# apollo2 register map
Vendor: Ambiq Micro; Series: Apollo; File version: 1.0
CPU: CM4 r1p0, little endian, MPU, FPU, 3 interrupt priority bits
Registers are 32-bit, read-write, reset 0x0 unless marked. A register's access mark holds for its fields unless they carry their own. Offsets are from the block's base; [hi:lo] are bit positions; 'fields as' and 'values as' point back to an identical list.

## CLKGEN — Clock Generator
Base 0x40004000
0x00 CALXT — XT Oscillator Control
  [10:0] CALXT — XT Oscillator calibration value
0x04 CALRC — RC Oscillator Control
  [17:0] CALRC — LFRC Oscillator calibration value
0x08 ACALCTR — Autocalibration Counter
  [23:0] ACALCTR — Autocalibration Counter result.
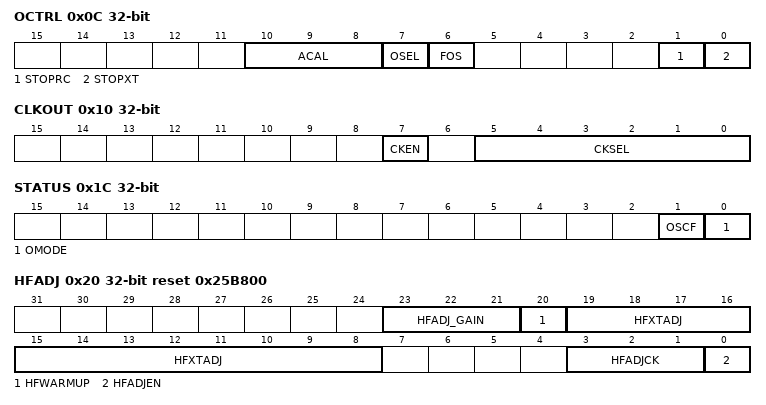
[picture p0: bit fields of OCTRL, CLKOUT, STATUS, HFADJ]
0x0C OCTRL — Oscillator Control
  [10:8] ACAL — Autocalibration control
    0=DIS (Disable Autocalibration value.); 2=1024SEC (Autocalibrate every 1024 seconds value.); 3=512SEC (Autocalibrate every 512 seconds value.); 6=XTFREQ (Frequency measurement using XT value.); 7=EXTFREQ (Frequency measurement using external clock value.)
  [7] OSEL — Selects the RTC oscillator (1 => LFRC, 0 => XT)
    0=RTC_XT (RTC uses the XT value.); 1=RTC_LFRC (RTC uses the LFRC value.)
  [6] FOS — Oscillator switch on failure function
    0=DIS (Disable the oscillator switch on failure function value.); 1=EN (Enable the oscillator switch on failure function value.)
  [1] STOPRC — Stop the LFRC Oscillator to the RTC
    0=EN (Enable the LFRC Oscillator to drive the RTC value.); 1=STOP (Stop the LFRC Oscillator when driving the RTC value.)
  [0] STOPXT — Stop the XT Oscillator to the RTC
    0=EN (Enable the XT Oscillator to drive the RTC value.); 1=STOP (Stop the XT Oscillator when driving the RTC value.)
0x10 CLKOUT — CLKOUT Frequency Select
  [7] CKEN — Enable the CLKOUT signal
    0=DIS (Disable CLKOUT value.); 1=EN (Enable CLKOUT value.)
  [5:0] CKSEL — CLKOUT signal select
    0=LFRC (LFRC value.); 1=XT_DIV2 (XT / 2 value.); 2=XT_DIV4 (XT / 4 value.); 3=XT_DIV8 (XT / 8 value.); 4=XT_DIV16 (XT / 16 value.); 5=XT_DIV32 (XT / 32 value.); 16=RTC_1Hz (1 Hz as selected in RTC value.); 22=XT_DIV2M (XT / 2^21 value.); 23=XT (XT value.); 24=CG_100Hz (100 Hz as selected in CLKGEN value.); 25=HFRC (HFRC value.); 26=HFRC_DIV4 (HFRC / 4 value.); 27=HFRC_DIV8 (HFRC / 8 value.); 28=HFRC_DIV16 (HFRC / 16 value.); 29=HFRC_DIV64 (HFRC / 64 value.); 30=HFRC_DIV128 (HFRC / 128 value.); 31=HFRC_DIV256 (HFRC / 256 value.); 32=HFRC_DIV512 (HFRC / 512 value.); 34=FLASH_CLK (Flash Clock value.); 35=LFRC_DIV2 (LFRC / 2 value.); 36=LFRC_DIV32 (LFRC / 32 value.); 37=LFRC_DIV512 (LFRC / 512 value.); 38=LFRC_DIV32K (LFRC / 32768 value.); 39=XT_DIV256 (XT / 256 value.); 40=XT_DIV8K (XT / 8192 value.); 41=XT_DIV64K (XT / 2^16 value.); 42=ULFRC_DIV16 (Uncal LFRC / 16 value.); 43=ULFRC_DIV128 (Uncal LFRC / 128 value.); 44=ULFRC_1Hz (Uncal LFRC / 1024 value.); 45=ULFRC_DIV4K (Uncal LFRC / 4096 value.); 46=ULFRC_DIV1M (Uncal LFRC / 2^20 value.); 47=HFRC_DIV64K (HFRC / 2^16 value.); 48=HFRC_DIV16M (HFRC / 2^24 value.); 49=LFRC_DIV2M (LFRC / 2^20 value.); 50=HFRCNE (HFRC (not autoenabled) value.); 51=HFRCNE_DIV8 (HFRC / 8 (not autoenabled) value.); 53=XTNE (XT (not autoenabled) value.); 54=XTNE_DIV16 (XT / 16 (not autoenabled) value.); 55=LFRCNE_DIV32 (LFRC / 32 (not autoenabled) value.); 57=LFRCNE (LFRC (not autoenabled) - Default for undefined values value.)
0x14 CLKKEY — Key Register for Clock Control Register
  [31:0] CLKKEY — Key register value.
    71=Key (Key value.)
0x18 CCTRL reset 0x1 — HFRC Clock Control
  [0] CORESEL — Core Clock divisor
    0=HFRC (Core Clock is HFRC value.); 1=HFRC_DIV2 (Core Clock is HFRC / 2 value.)
0x1C STATUS — Clock Generator Status
  [1] OSCF — XT Oscillator is enabled but not oscillating
  [0] OMODE — Current RTC oscillator (1 => LFRC, 0 => XT)
0x20 HFADJ reset 0x25B800 — HFRC Adjustment
  [23:21] HFADJ_GAIN — Gain control for HFRC adjustment
    0=Gain_of_1 (HF Adjust with Gain of 1 value.); 1=Gain_of_1_in_2 (HF Adjust with Gain of 0.5 value.); 2=Gain_of_1_in_4 (HF Adjust with Gain of 0.25 value.); 3=Gain_of_1_in_8 (HF Adjust with Gain of 0.125 value.); 4=Gain_of_1_in_16 (HF Adjust with Gain of 0.0625 value.); 5=Gain_of_1_in_32 (HF Adjust with Gain of 0.03125 value.)
  [20] HFWARMUP — XT warmup period for HFRC adjustment
    0=1SEC (Autoadjust XT warmup period = 1-2 seconds value.); 1=2SEC (Autoadjust XT warmup period = 2-4 seconds value.)
  [19:8] HFXTADJ — Target HFRC adjustment value.
  [3:1] HFADJCK — Repeat period for HFRC adjustment
    0=4SEC (Autoadjust repeat period = 4 seconds value.); 1=16SEC (Autoadjust repeat period = 16 seconds value.); 2=32SEC (Autoadjust repeat period = 32 seconds value.); 3=64SEC (Autoadjust repeat period = 64 seconds value.); 4=128SEC (Autoadjust repeat period = 128 seconds value.); 5=256SEC (Autoadjust repeat period = 256 seconds value.); 6=512SEC (Autoadjust repeat period = 512 seconds value.); 7=1024SEC (Autoadjust repeat period = 1024 seconds value.)
  [0] HFADJEN — HFRC adjustment control
    0=DIS (Disable the HFRC adjustment value.); 1=EN (Enable the HFRC adjustment value.)
0x24 HFVAL — HFADJ readback
  [10:0] HFTUNERB — Current HFTUNE value
0x28 CLOCKEN — Clock Enable Status
  [31:0] CLOCKEN — Clock enable status
    1=ADC_CLKEN (Clock enable for the ADC. value.); 2=CTIMER_CLKEN (Clock enable for the CTIMER. value.); 4=CTIMER0A_CLKEN (Clock enable for the CTIMER0A. value.); 8=CTIMER0B_CLKEN (Clock enable for the CTIMER0B. value.); 16=CTIMER1A_CLKEN (Clock enable for the CTIMER1A. value.); 32=CTIMER1B_CLKEN (Clock enable for the CTIMER1B. value.); 64=CTIMER2A_CLKEN (Clock enable for the CTIMER2A. value.); 128=CTIMER2B_CLKEN (Clock enable for the CTIMER2B. value.); 0x100=CTIMER3A_CLKEN (Clock enable for the CTIMER3A. value.); 0x200=CTIMER3B_CLKEN (Clock enable for the CTIMER3B. value.); 0x400=IOMSTR0_CLKEN (Clock enable for the IO Master 0. value.); 0x800=IOMSTR1_CLKEN (Clock enable for the IO Master 1. value.); 0x1000=IOMSTR2_CLKEN (Clock enable for the IO Master 2. value.); 0x2000=IOMSTR3_CLKEN (Clock enable for the IO Master 3. value.); 0x4000=IOMSTR4_CLKEN (Clock enable for the IO Master 4. value.); 0x8000=IOMSTR5_CLKEN (Clock enable for the IO Master 5. value.); 0x10000=IOMSTRIFC0_CLKEN (Clock enable for the IO Master IFC0. value.); 0x20000=IOMSTRIFC1_CLKEN (Clock enable for the IO Master IFC1. value.); 0x40000=IOMSTRIFC2_CLKEN (Clock enable for the IO Master IFC2. value.); 0x80000=IOMSTRIFC3_CLKEN (Clock enable for the IO Master IFC3. value.); 0x100000=IOMSTRIFC4_CLKEN (Clock enable for the IO Master IFC4. value.); 0x200000=IOMSTRIFC5_CLKEN (Clock enable for the IO Master IFC5. value.); 0x400000=IOSLAVE_CLKEN (Clock enable for the IO Slave. value.); 0x800000=PDM_CLKEN (Clock enable for the PDM. value.); 0x1000000=PDMIFC_CLKEN (Clock enable for the PDM IFC. value.); 0x2000000=RSTGEN_CLKEN (Clock enable for the RSTGEN. value.); 0x4000000=SRAM_WIPE_CLKEN (Clock enable for the SRAM_WIPE. value.); 0x8000000=STIMER_CLKEN (Clock enable for the STIMER. value.); 0x10000000=STIMER_CNT_CLKEN (Clock enable for the STIMER_CNT. value.); 0x20000000=TPIU_CLKEN (Clock enable for the TPIU. value.); 0x40000000=UART0_HCLK_CLKEN (Clock enable for the UART0_HCLK. value.); 0x80000000=UART0HF_CLKEN (Clock enable for the UART0HF. value.)
0x2C CLOCKEN2 — Clock Enable Status
  [31:0] CLOCKEN2 — Clock enable status 2
    1=UART1_HCLK_CLKEN (Clock enable for the UART1_HCLK. value.); 2=UART1HF_CLKEN (Clock enable for the UART1HF. value.); 4=WDT_CLKEN (Clock enable for the WDT. value.); 0x40000000=XT_32KHz_EN (Clock enable for the XT_32KHz. value.); 0x80000000=FRCHFRC (Force HFRC On Status. value.)
0x30 CLOCKEN3 — Clock Enable Status
  [31:0] CLOCKEN3 — Clock enable status 3
    0x1000000=periph_all_xtal_en (At least 1 peripherial is requesting for XTAL Clock value.); 0x2000000=periph_all_hfrc_en (At least 1 peripherial is requesting for HFRC Clock value.); 0x4000000=HFADJEN (HFRC Adjust Enable Status value.); 0x8000000=HFRC_en_out (HFRC is enabled during adjustment status value.); 0x10000000=RTC_SOURCE (Selects the RTC oscillator (0 => LFRC, 1 => XT) value.); 0x20000000=XTAL_EN (XT is enabled Status value.); 0x40000000=HFRC_EN (HFRC is enabled Status value.); 0x80000000=FLASHCLK_EN (Flash Clock is enabled Status value.)
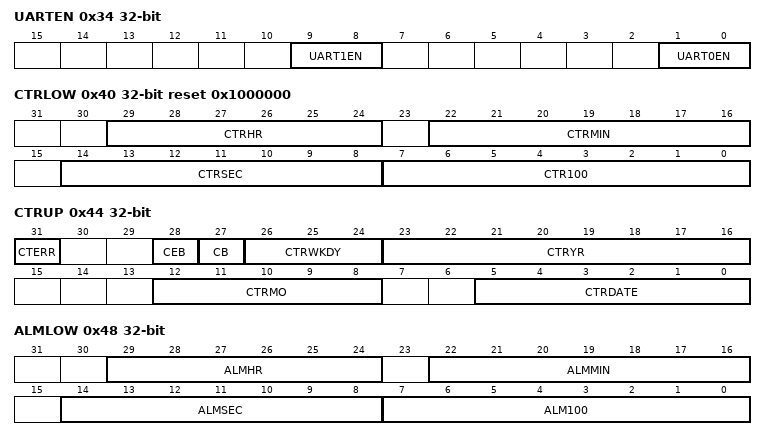
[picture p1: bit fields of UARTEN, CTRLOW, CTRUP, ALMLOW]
0x34 UARTEN — UART Enable
  [9:8] UART1EN — UART1 system clock control
    0=DIS (Disable the UART1 system clock value.); 1=EN (Enable the UART1 system clock value.); 2=REDUCE_FREQ (Run UART_Hclk at the same frequency as UART_hfclk value.); 3=EN_POWER_SAV (Enable UART_hclk to reduce to UART_hfclk at low power mode value.)
  [1:0] UART0EN — UART0 system clock control
    0=DIS (Disable the UART0 system clock value.); 1=EN (Enable the UART0 system clock value.); 2=REDUCE_FREQ (Run UART_Hclk at the same frequency as UART_hfclk value.); 3=EN_POWER_SAV (Enable UART_hclk to reduce to UART_hfclk at low power mode value.)
0x40 CTRLOW reset 0x1000000 — RTC Counters Lower
  [29:24] CTRHR — Hours Counter
  [22:16] CTRMIN — Minutes Counter
  [14:8] CTRSEC — Seconds Counter
  [7:0] CTR100 — 100ths of a second Counter
0x44 CTRUP — RTC Counters Upper
  [31] CTERR — Counter read error status
    0=NOERR (No read error occurred value.); 1=RDERR (Read error occurred value.)
  [28] CEB — Century enable
    0=DIS (Disable the Century bit from changing value.); 1=EN (Enable the Century bit to change value.)
  [27] CB — Century
    0=Century is 2000s value; 1=1900_2100 (Century is 1900s/2100s value.)
  [26:24] CTRWKDY — Weekdays Counter
  [23:16] CTRYR — Years Counter
  [12:8] CTRMO — Months Counter
  [5:0] CTRDATE — Date Counter
0x48 ALMLOW — RTC Alarms Lower
  [29:24] ALMHR — Hours Alarm
  [22:16] ALMMIN — Minutes Alarm
  [14:8] ALMSEC — Seconds Alarm
  [7:0] ALM100 — 100ths of a second Alarm
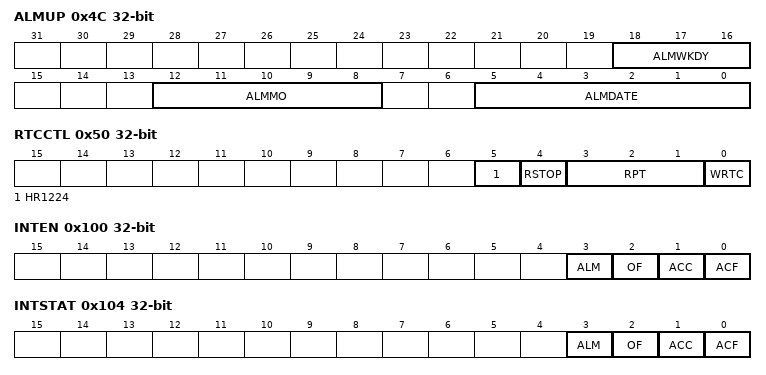
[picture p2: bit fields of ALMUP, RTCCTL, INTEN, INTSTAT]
0x4C ALMUP — RTC Alarms Upper
  [18:16] ALMWKDY — Weekdays Alarm
  [12:8] ALMMO — Months Alarm
  [5:0] ALMDATE — Date Alarm
0x50 RTCCTL — RTC Control Register
  [5] HR1224 — Hours Counter mode
    0=24HR (Hours in 24 hour mode value.); 1=12HR (Hours in 12 hour mode value.)
  [4] RSTOP — RTC input clock control
    0=RUN (Allow the RTC input clock to run value.); 1=STOP (Stop the RTC input clock value.)
  [3:1] RPT — Alarm repeat interval
    0=DIS (Alarm interrupt disabled value.); 1=YEAR (Interrupt every year value.); 2=MONTH (Interrupt every month value.); 3=WEEK (Interrupt every week value.); 4=DAY (Interrupt every day value.); 5=HR (Interrupt every hour value.); 6=MIN (Interrupt every minute value.); 7=SEC (Interrupt every second/10th/100th value.)
  [0] WRTC — Counter write control
    0=DIS (Counter writes are disabled value.); 1=EN (Counter writes are enabled value.)
0x100 INTEN — CLKGEN Interrupt Register: Enable
  [3] ALM — RTC Alarm interrupt
  [2] OF — XT Oscillator Fail interrupt
  [1] ACC — Autocalibration Complete interrupt
  [0] ACF — Autocalibration Fail interrupt
0x104 INTSTAT — CLKGEN Interrupt Register: Status
  fields as INTEN
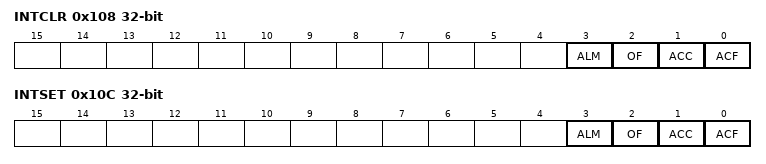
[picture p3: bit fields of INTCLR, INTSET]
0x108 INTCLR — CLKGEN Interrupt Register: Clear
  fields as INTEN
0x10C INTSET — CLKGEN Interrupt Register: Set
  fields as INTEN
